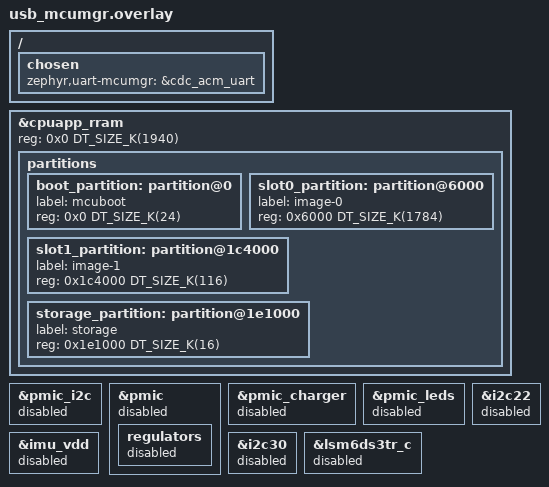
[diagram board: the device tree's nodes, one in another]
/*
 * Keep the USB firmware-loader image aligned with Nordic's nRF54LM20B
 * single_slot layout, while trimming XIAO board peripherals not used by
 * the loader image.
 */

/delete-node/ &boot_partition;
/delete-node/ &slot0_partition;
/delete-node/ &slot0_ns_partition;
/delete-node/ &slot1_partition;
/delete-node/ &slot1_ns_partition;
/delete-node/ &storage_partition;

/ {
	chosen {
		zephyr,uart-mcumgr = &cdc_acm_uart;
	};
};

&cpuapp_rram {
	reg = <0x0 DT_SIZE_K(1940)>;

	partitions {
		boot_partition: partition@0 {
			label = "mcuboot";
			reg = <0x0 DT_SIZE_K(24)>;
		};

		slot0_partition: partition@6000 {
			label = "image-0";
			reg = <0x6000 DT_SIZE_K(1784)>;
		};

		slot1_partition: partition@1c4000 {
			label = "image-1";
			reg = <0x1c4000 DT_SIZE_K(116)>;
		};

		storage_partition: partition@1e1000 {
			label = "storage";
			reg = <0x1e1000 DT_SIZE_K(16)>;
		};
	};
};

&pmic_i2c {
	status = "disabled";
};

&pmic {
	status = "disabled";

	regulators {
		status = "disabled";
	};
};

&pmic_charger {
	status = "disabled";
};

&pmic_leds {
	status = "disabled";
};

&imu_vdd {
	status = "disabled";
};

&i2c22 {
	status = "disabled";
};

&i2c30 {
	status = "disabled";
};

&lsm6ds3tr_c {
	status = "disabled";
};
